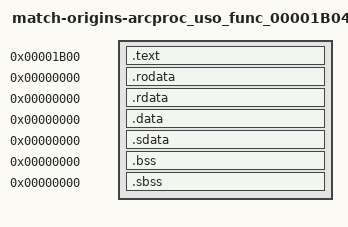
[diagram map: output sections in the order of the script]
/* Standard linker bindings; original USO identity is independently audited. */
SECTIONS {
 .text 0x1b00 : SUBALIGN(4) { *(.text) *(.text.*) }
 .rodata 0x0 : SUBALIGN(4) { *(.rodata) *(.rodata.*) }
 .rdata 0x0 : SUBALIGN(4) { *(.rdata) *(.rdata.*) }
 .data 0x0 : SUBALIGN(4) { *(.data) *(.data.*) }
 .sdata 0x0 : SUBALIGN(4) { *(.sdata) *(.sdata.*) }
 .bss 0x0 : SUBALIGN(4) { *(.bss) *(.bss.*) }
 .sbss 0x0 : SUBALIGN(4) { *(.sbss) *(.sbss.*) }
 /DISCARD/ : { *(.mdebug) *(.reginfo) *(.pdr) *(.comment) *(.MIPS.abiflags) *(.options) }
}
D_arc1B04_a = 0x0;
arcproc_uso_import_116_1B04 = 0x0;
arcproc_uso_import_117_1B04 = 0x0;
arcproc_uso_import_165_1B04 = 0x0;
